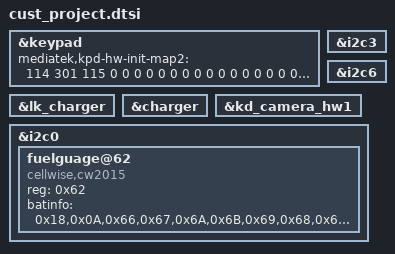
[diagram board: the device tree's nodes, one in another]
//add by lipengpeng 20210223 start
&keypad {
       mediatek,kpd-hw-init-map2 = <114 301 115 0 0 0 0 0 0 0
    0 0 0 0 0 0 0 0 0
    0 0 0 0 0 0 0 0 0
    0 0 0 0 0 0 0 0 0
    0 0 0 0 0 0 0 0 0
    0 0 0 0 0 0 0 0 0
    0 0 0 0 0 0 0 0 0
    0 0 0 0 0 0 0 0 >;

};
//add by lipengpeng 20210223 end

&lk_charger{
	//ac_charger_current = <3200000>;
	//ac_charger_input_current = <3000000>;
};

&charger{
	//ac_charger_current = <3200000>;
	//ac_charger_input_current = <3000000>;
};


&i2c3 {
//	spc@21 {
//		compatible = "prize,spc_r";
//		status = "disable";
//	};
};

&i2c6 {
//	spc_f@21 {
//		compatible = "prize,spc_r_1";
//		status = "disable";
//	};
};

&kd_camera_hw1 {
	//cam2_enable_sensor = "imx350_mipi_raw imx386_mipi_mono";//prize
};

&i2c0 {
	fuelguage@62 {
		compatible = "cellwise,cw2015";
		reg = <0x62>;
		batinfo = /bits/ 8 <0x18,0x0A,0x66,0x67,0x6A,0x6B,0x69,0x68,0x62,0x64,0x65,0x57,0x64,0x58,0x49,0x41,0x37,
							0x31,0x28,0x22,0x23,0x34,0x44,0x4A,0x23,0x4A,0x0B,0x85,0x20,0x3F,0x42,0x4F,0x5D,0x60,
							0x61,0x62,0x3E,0x1B,0x6E,0x50,0x0B,0x23,0x33,0x60,0x80,0x96,0xA0,0x0F,0x22,0x70,0x99,
							0xA3,0x80,0x8B,0xC1,0xCB,0x2F,0x00,0x64,0xA5,0xB5,0x0E,0x09,0x89>;
	};
};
